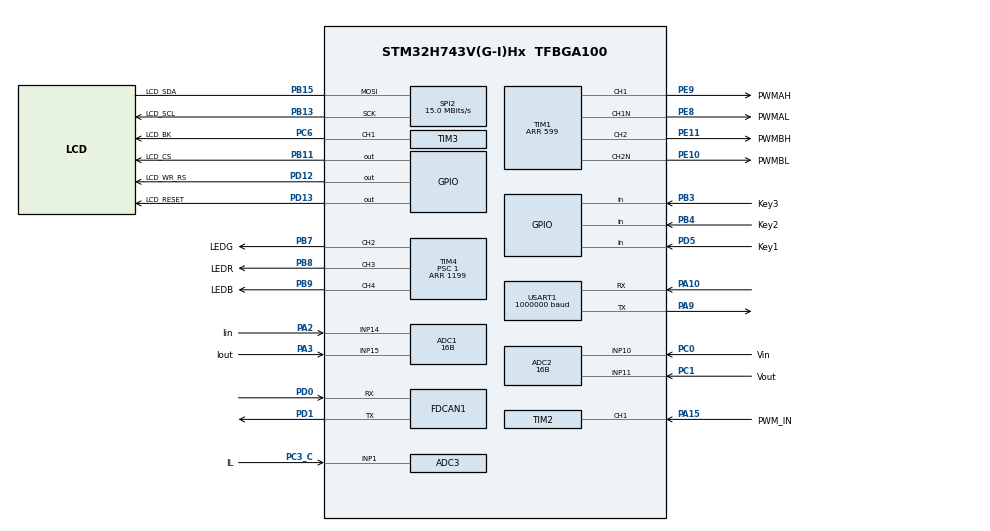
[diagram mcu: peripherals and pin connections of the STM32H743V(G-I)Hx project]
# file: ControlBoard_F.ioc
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ADC1.Channel-1\#ChannelRegularConversion=ADC_CHANNEL_14
ADC1.Channel-2\#ChannelRegularConversion=ADC_CHANNEL_15
ADC1.ClockPrescaler=ADC_CLOCK_SYNC_PCLK_DIV4
ADC1.ClockPrescalerADC3=ADC_CLOCK_SYNC_PCLK_DIV4
ADC1.ConversionDataManagement=ADC_CONVERSIONDATA_DMA_CIRCULAR
ADC1.EOCSelection=ADC_EOC_SEQ_CONV
ADC1.ExternalTrigConv=ADC_EXTERNALTRIG_T1_TRGO
ADC1.NbrOfConversion=2
ADC1.NbrOfConversionFlag=1
ADC1.OffsetNumber-1\#ChannelRegularConversion=ADC_OFFSET_NONE
ADC1.OffsetNumber-2\#ChannelRegularConversion=ADC_OFFSET_NONE
ADC1.OffsetSignedSaturation-1\#ChannelRegularConversion=DISABLE
ADC1.OffsetSignedSaturation-2\#ChannelRegularConversion=DISABLE
ADC1.Overrun=ADC_OVR_DATA_OVERWRITTEN
ADC1.Rank-1\#ChannelRegularConversion=1
ADC1.Rank-2\#ChannelRegularConversion=2
ADC1.Resolution=ADC_RESOLUTION_16B
ADC1.SamplingTime-1\#ChannelRegularConversion=ADC_SAMPLETIME_387CYCLES_5
ADC1.SamplingTime-2\#ChannelRegularConversion=ADC_SAMPLETIME_387CYCLES_5
ADC1.master=1
ADC2.Channel-1\#ChannelRegularConversion=ADC_CHANNEL_10
ADC2.Channel-2\#ChannelRegularConversion=ADC_CHANNEL_11
ADC2.ClockPrescaler=ADC_CLOCK_SYNC_PCLK_DIV4
ADC2.ClockPrescalerADC3=ADC_CLOCK_SYNC_PCLK_DIV4
ADC2.ConversionDataManagement=ADC_CONVERSIONDATA_DMA_CIRCULAR
ADC2.EOCSelection=ADC_EOC_SEQ_CONV
ADC2.ExternalTrigConv=ADC_EXTERNALTRIG_T1_TRGO
ADC2.NbrOfConversion=2
ADC2.NbrOfConversionFlag=1
ADC2.OffsetNumber-1\#ChannelRegularConversion=ADC_OFFSET_NONE
ADC2.OffsetNumber-2\#ChannelRegularConversion=ADC_OFFSET_NONE
ADC2.OffsetSignedSaturation-1\#ChannelRegularConversion=DISABLE
ADC2.OffsetSignedSaturation-2\#ChannelRegularConversion=DISABLE
ADC2.Overrun=ADC_OVR_DATA_OVERWRITTEN
ADC2.Rank-1\#ChannelRegularConversion=1
ADC2.Rank-2\#ChannelRegularConversion=2
ADC2.Resolution=ADC_RESOLUTION_16B
ADC2.SamplingTime-1\#ChannelRegularConversion=ADC_SAMPLETIME_387CYCLES_5
ADC2.SamplingTime-2\#ChannelRegularConversion=ADC_SAMPLETIME_387CYCLES_5
ADC3.Channel-1\#ChannelRegularConversion=ADC_CHANNEL_1
ADC3.ClockPrescaler=ADC_CLOCK_SYNC_PCLK_DIV4
ADC3.ClockPrescalerADC3=ADC_CLOCK_SYNC_PCLK_DIV4
ADC3.ConversionDataManagement=ADC_CONVERSIONDATA_DMA_CIRCULAR
ADC3.EOCSelection=ADC_EOC_SEQ_CONV
ADC3.ExternalTrigConv=ADC_EXTERNALTRIG_T1_TRGO
ADC3.NbrOfConversion=1
ADC3.NbrOfConversionFlag=1
ADC3.OffsetNumber-1\#ChannelRegularConversion=ADC_OFFSET_NONE
ADC3.OffsetSignedSaturation-1\#ChannelRegularConversion=DISABLE
ADC3.Overrun=ADC_OVR_DATA_OVERWRITTEN
ADC3.Rank-1\#ChannelRegularConversion=1
ADC3.Resolution=ADC_RESOLUTION_16B
ADC3.SamplingTime-1\#ChannelRegularConversion=ADC_SAMPLETIME_387CYCLES_5
CORTEX_M7.default_mode_Activation=1
Dma.ADC1.0.Direction=DMA_PERIPH_TO_MEMORY
Dma.ADC1.0.EventEnable=DISABLE
Dma.ADC1.0.FIFOMode=DMA_FIFOMODE_DISABLE
Dma.ADC1.0.Instance=DMA1_Stream0
Dma.ADC1.0.MemDataAlignment=DMA_MDATAALIGN_HALFWORD
Dma.ADC1.0.MemInc=DMA_MINC_ENABLE
Dma.ADC1.0.Mode=DMA_CIRCULAR
Dma.ADC1.0.PeriphDataAlignment=DMA_PDATAALIGN_HALFWORD
Dma.ADC1.0.PeriphInc=DMA_PINC_DISABLE
Dma.ADC1.0.Polarity=HAL_DMAMUX_REQ_GEN_RISING
Dma.ADC1.0.Priority=DMA_PRIORITY_LOW
Dma.ADC1.0.RequestNumber=1
Dma.ADC1.0.SignalID=NONE
Dma.ADC1.0.SyncEnable=DISABLE
Dma.ADC1.0.SyncPolarity=HAL_DMAMUX_SYNC_NO_EVENT
Dma.ADC1.0.SyncRequestNumber=1
Dma.ADC1.0.SyncSignalID=NONE
Dma.ADC2.1.Direction=DMA_PERIPH_TO_MEMORY
Dma.ADC2.1.EventEnable=DISABLE
Dma.ADC2.1.FIFOMode=DMA_FIFOMODE_DISABLE
Dma.ADC2.1.Instance=DMA2_Stream0
Dma.ADC2.1.MemDataAlignment=DMA_MDATAALIGN_HALFWORD
Dma.ADC2.1.MemInc=DMA_MINC_ENABLE
Dma.ADC2.1.Mode=DMA_CIRCULAR
Dma.ADC2.1.PeriphDataAlignment=DMA_PDATAALIGN_HALFWORD
Dma.ADC2.1.PeriphInc=DMA_PINC_DISABLE
Dma.ADC2.1.Polarity=HAL_DMAMUX_REQ_GEN_RISING
Dma.ADC2.1.Priority=DMA_PRIORITY_LOW
Dma.ADC2.1.RequestNumber=1
Dma.ADC2.1.SignalID=NONE
Dma.ADC2.1.SyncEnable=DISABLE
Dma.ADC2.1.SyncPolarity=HAL_DMAMUX_SYNC_NO_EVENT
Dma.ADC2.1.SyncRequestNumber=1
Dma.ADC2.1.SyncSignalID=NONE
Dma.ADC3.2.Direction=DMA_PERIPH_TO_MEMORY
Dma.ADC3.2.EventEnable=DISABLE
Dma.ADC3.2.FIFOMode=DMA_FIFOMODE_DISABLE
Dma.ADC3.2.Instance=DMA1_Stream3
Dma.ADC3.2.MemDataAlignment=DMA_MDATAALIGN_HALFWORD
Dma.ADC3.2.MemInc=DMA_MINC_ENABLE
Dma.ADC3.2.Mode=DMA_CIRCULAR
Dma.ADC3.2.PeriphDataAlignment=DMA_PDATAALIGN_HALFWORD
Dma.ADC3.2.PeriphInc=DMA_PINC_DISABLE
Dma.ADC3.2.Polarity=HAL_DMAMUX_REQ_GEN_RISING
Dma.ADC3.2.Priority=DMA_PRIORITY_LOW
Dma.ADC3.2.RequestNumber=1
Dma.ADC3.2.SignalID=NONE
Dma.ADC3.2.SyncEnable=DISABLE
Dma.ADC3.2.SyncPolarity=HAL_DMAMUX_SYNC_NO_EVENT
Dma.ADC3.2.SyncRequestNumber=1
Dma.ADC3.2.SyncSignalID=NONE
Dma.Request0=ADC1
Dma.Request1=ADC2
Dma.Request2=ADC3
FDCAN1.CalculateBaudRateNominal=999999
FDCAN1.CalculateTimeBitNominal=1000
FDCAN1.CalculateTimeQuantumNominal=41.66666666666667
FDCAN1.DataPrescaler=5
FDCAN1.DataTimeSeg1=17
FDCAN1.DataTimeSeg2=6
FDCAN1.FrameFormat=FDCAN_FRAME_CLASSIC
FDCAN1.NominalPrescaler=5
FDCAN1.NominalTimeSeg1=17
FDCAN1.NominalTimeSeg2=6
FDCAN1.RxFifo0ElmtSize=FDCAN_DATA_BYTES_16
FDCAN1.RxFifo0ElmtsNbr=10
FDCAN1.StdFiltersNbr=1
FDCAN1.TxElmtSize=FDCAN_DATA_BYTES_16
FDCAN1.TxFifoQueueElmtsNbr=10
Mcu.Family=STM32H7
Mcu.Name=STM32H743V(G-I)Hx
Mcu.Package=TFBGA100
NVIC.ADC3_IRQn=true\:0\:0\:false\:false\:true\:true\:true\:true
NVIC.ADC_IRQn=true\:0\:0\:false\:false\:true\:true\:true\:true
NVIC.DMA1_Stream0_IRQn=true\:0\:0\:false\:false\:true\:false\:true\:true
NVIC.DMA1_Stream3_IRQn=true\:0\:0\:false\:false\:true\:false\:true\:true
NVIC.DMA2_Stream0_IRQn=true\:0\:0\:false\:false\:true\:false\:true\:true
NVIC.FDCAN1_IT0_IRQn=true\:0\:0\:false\:false\:true\:true\:true\:true
NVIC.PriorityGroup=NVIC_PRIORITYGROUP_4
NVIC.TIM2_IRQn=true\:0\:0\:false\:false\:true\:true\:true\:true
NVIC.TIM7_IRQn=true\:0\:0\:true\:false\:true\:true\:true\:true
PA10.Mode=Asynchronous
PA10.Signal=USART1_RX
PA13\ (JTMS/SWDIO).Mode=Serial_Wire
PA13\ (JTMS/SWDIO).Signal=DEBUG_JTMS-SWDIO
PA14\ (JTCK/SWCLK).Mode=Serial_Wire
PA14\ (JTCK/SWCLK).Signal=DEBUG_JTCK-SWCLK
PA15\ (JTDI).GPIO_Label=PWM_IN
PA15\ (JTDI).Signal=S_TIM2_CH1_ETR
PA2.GPIO_Label=Iin
PA2.Signal=ADCx_INP14
PA3.GPIO_Label=Iout
PA3.Signal=ADCx_INP15
PA9.Mode=Asynchronous
PA9.Signal=USART1_TX
PB11.GPIO_Label=LCD_CS
PB11.Signal=GPIO_Output
PB13.GPIO_Label=LCD_SCL
PB13.Mode=Simplex_Bidirectional_Master
PB13.Signal=SPI2_SCK
PB15.GPIO_Label=LCD_SDA
PB15.Mode=Simplex_Bidirectional_Master
PB15.Signal=SPI2_MOSI
PB3\ (JTDO/TRACESWO).GPIO_Label=Key3
PB3\ (JTDO/TRACESWO).Signal=GPIO_Input
PB4\ (NJTRST).GPIO_Label=Key2
PB4\ (NJTRST).Signal=GPIO_Input
PB7.GPIO_Label=LEDG
PB7.Signal=S_TIM4_CH2
PB8.GPIO_Label=LEDR
PB8.Signal=S_TIM4_CH3
PB9.GPIO_Label=LEDB
PB9.Signal=S_TIM4_CH4
PC0.GPIO_Label=Vin
PC0.Signal=ADCx_INP10
PC1.GPIO_Label=Vout
PC1.Signal=ADCx_INP11
PC3_C.GPIO_Label=IL
PC3_C.Mode=IN1-Single-Ended
PC3_C.Signal=ADC3_INP1
PC6.GPIO_Label=LCD_BK
PC6.Signal=S_TIM3_CH1
PD0.Mode=FDCAN_Activate
PD0.Signal=FDCAN1_RX
PD1.Mode=FDCAN_Activate
PD1.Signal=FDCAN1_TX
PD12.GPIO_Label=LCD_WR_RS
PD12.Signal=GPIO_Output
PD13.GPIO_Label=LCD_RESET
PD13.Signal=GPIO_Output
PD5.GPIO_Label=Key1
PD5.Signal=GPIO_Input
PE10.GPIO_Label=PWMBL
PE10.GPIO_Speed=GPIO_SPEED_FREQ_VERY_HIGH
PE10.Mode=PWM Generation2 CH2 CH2N
PE10.Signal=TIM1_CH2N
PE11.GPIO_Label=PWMBH
PE11.GPIO_Speed=GPIO_SPEED_FREQ_VERY_HIGH
PE11.Signal=S_TIM1_CH2
PE8.GPIO_Label=PWMAL
PE8.GPIO_Speed=GPIO_SPEED_FREQ_VERY_HIGH
PE8.Mode=PWM Generation1 CH1 CH1N
PE8.Signal=TIM1_CH1N
PE9.GPIO_Label=PWMAH
PE9.GPIO_Speed=GPIO_SPEED_FREQ_VERY_HIGH
PE9.Signal=S_TIM1_CH1
PH0-OSC_IN\ (PH0).Mode=HSE-External-Clock-Source
PH0-OSC_IN\ (PH0).Signal=RCC_OSC_IN
ProjectManager.HeapSize=0x200
ProjectManager.StackSize=0x400
ProjectManager.TargetToolchain=STM32CubeIDE
RCC.ADCFreq_Value=100000000
RCC.APB1Freq_Value=120000000
RCC.APB2Freq_Value=120000000
RCC.APB3Freq_Value=120000000
RCC.APB4Freq_Value=120000000
RCC.CortexFreq_Value=480000000
RCC.D1PPRE=RCC_APB3_DIV2
RCC.D2PPRE1=RCC_APB1_DIV2
RCC.D2PPRE2=RCC_APB2_DIV2
RCC.D3PPRE=RCC_APB4_DIV2
RCC.DIVM1=5
RCC.DIVM2=20
RCC.DIVN1=192
RCC.DIVN2=160
RCC.DIVQ1=8
RCC.HCLKFreq_Value=240000000
RCC.HPRE=RCC_HCLK_DIV2
RCC.PLL2FRACN=0
RCC.PLL3FRACN=0
RCC.PLLFRACN=0
RCC.PLLSourceVirtual=RCC_PLLSOURCE_HSE
RCC.SYSCLKFreq_VALUE=480000000
RCC.SYSCLKSource=RCC_SYSCLKSOURCE_PLLCLK
RCC.Tim1Mul=2
RCC.USBFreq_Value=120000000
SH.ADCx_INP10.0=ADC1_INP10
SH.ADCx_INP10.1=ADC2_INP10,IN10-Single-Ended
SH.ADCx_INP11.0=ADC1_INP11
SH.ADCx_INP11.1=ADC2_INP11,IN11-Single-Ended
SH.ADCx_INP14.0=ADC2_INP14
SH.ADCx_INP14.1=ADC1_INP14,IN14-Single-Ended
SH.ADCx_INP15.0=ADC2_INP15
SH.ADCx_INP15.1=ADC1_INP15,IN15-Single-Ended
SH.S_TIM1_CH1.0=TIM1_CH1,PWM Generation1 CH1 CH1N
SH.S_TIM1_CH2.0=TIM1_CH2,PWM Generation2 CH2 CH2N
SH.S_TIM2_CH1_ETR.0=TIM2_CH1,Input_Capture1_from_TI1
SH.S_TIM3_CH1.0=TIM3_CH1,PWM Generation1 CH1
SH.S_TIM4_CH2.0=TIM4_CH2,PWM Generation2 CH2
SH.S_TIM4_CH3.0=TIM4_CH3,PWM Generation3 CH3
SH.S_TIM4_CH4.0=TIM4_CH4,PWM Generation4 CH4
SPI2.BaudRatePrescaler=SPI_BAUDRATEPRESCALER_8
SPI2.CalculateBaudRate=15.0 MBits/s
SPI2.DataSize=SPI_DATASIZE_8BIT
SPI2.Direction=SPI_DIRECTION_1LINE
SPI2.Mode=SPI_MODE_MASTER
SPI2.VirtualType=VM_MASTER
TIM1.AutoReloadPreload=TIM_AUTORELOAD_PRELOAD_DISABLE
TIM1.AutomaticOutput=TIM_AUTOMATICOUTPUT_ENABLE
TIM1.Channel-PWM\ Generation1\ CH1\ CH1N=TIM_CHANNEL_1
TIM1.Channel-PWM\ Generation2\ CH2\ CH2N=TIM_CHANNEL_2
TIM1.CounterMode=TIM_COUNTERMODE_CENTERALIGNED1
TIM1.DeadTime=50
TIM1.OCFastMode_PWM-PWM\ Generation1\ CH1\ CH1N=TIM_OCFAST_ENABLE
TIM1.OCFastMode_PWM-PWM\ Generation2\ CH2\ CH2N=TIM_OCFAST_ENABLE
TIM1.OCMode_PWM-PWM\ Generation1\ CH1\ CH1N=TIM_OCMODE_PWM2
TIM1.OCMode_PWM-PWM\ Generation2\ CH2\ CH2N=TIM_OCMODE_PWM2
TIM1.OffStateIDLEMode=TIM_OSSI_ENABLE
TIM1.OffStateRunMode=TIM_OSSR_ENABLE
TIM1.Period=599
TIM1.RepetitionCounter=3
TIM1.TIM_MasterOutputTrigger=TIM_TRGO_UPDATE
TIM1.TIM_MasterOutputTrigger2=TIM_TRGO2_RESET
TIM2.AutoReloadPreload=TIM_AUTORELOAD_PRELOAD_ENABLE
TIM2.Channel-Input_Capture1_from_TI1=TIM_CHANNEL_1
TIM2.ICPolarity_CH1=TIM_INPUTCHANNELPOLARITY_BOTHEDGE
TIM2.Period=999
TIM2.Prescaler=119
TIM3.AutoReloadPreload=TIM_AUTORELOAD_PRELOAD_ENABLE
TIM3.Channel-PWM\ Generation1\ CH1=TIM_CHANNEL_1
TIM3.Period=1199
TIM3.Prescaler=1
TIM4.AutoReloadPreload=TIM_AUTORELOAD_PRELOAD_ENABLE
TIM4.Channel-PWM\ Generation2\ CH2=TIM_CHANNEL_2
TIM4.Channel-PWM\ Generation3\ CH3=TIM_CHANNEL_3
TIM4.Channel-PWM\ Generation4\ CH4=TIM_CHANNEL_4
TIM4.OCPolarity_2=TIM_OCPOLARITY_LOW
TIM4.OCPolarity_3=TIM_OCPOLARITY_LOW
TIM4.OCPolarity_4=TIM_OCPOLARITY_LOW
TIM4.Period=1199
TIM4.Prescaler=1
TIM7.AutoReloadPreload=TIM_AUTORELOAD_PRELOAD_ENABLE
TIM7.Period=11999
TIM7.Prescaler=199
USART1.BaudRate=1000000
USART1.VirtualMode-Asynchronous=VM_ASYNC
VP_TIM1_VS_ClockSourceINT.Mode=Internal
VP_TIM2_VS_ClockSourceINT.Mode=Internal
VP_TIM3_VS_ClockSourceINT.Mode=Internal
VP_TIM4_VS_ClockSourceINT.Mode=Internal
VP_TIM7_VS_ClockSourceINT.Mode=Enable_Timer
board=custom

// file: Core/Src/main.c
/* USER CODE BEGIN Header */
/**
 ******************************************************************************
 * @file           : main.c
 * @brief          : Main program body
 ******************************************************************************
 * @attention
 *
 * Copyright (c) 2024 STMicroelectronics.
 * All rights reserved.
 *
 * This software is licensed under terms that can be found in the LICENSE file
 * in the root directory of this software component.
 * If no LICENSE file comes with this software, it is provided AS-IS.
 *
 ******************************************************************************
 */
/* USER CODE END Header */
#include "main.h"
#include "adc.h"
#include "dma.h"
#include "fdcan.h"
#include "spi.h"
#include "tim.h"
#include "usart.h"
#include "gpio.h"

/* USER CODE BEGIN Includes */
#include <usermain.hpp>
/* USER CODE END Includes */

void SystemClock_Config(void);
static void MPU_Config(void);

int main(void)
{

  /* MPU Configuration--------------------------------------------------------*/
  MPU_Config();

  /* MCU Configuration--------------------------------------------------------*/

  /* Reset of all peripherals, Initializes the Flash interface and the Systick. */
  HAL_Init();

  /* Configure the system clock */
  SystemClock_Config();

  /* Initialize all configured peripherals */
  MX_GPIO_Init();
  MX_DMA_Init();
  MX_FDCAN1_Init();
  MX_TIM1_Init();
  MX_ADC2_Init();
  MX_ADC3_Init();
  MX_ADC1_Init();
  MX_USART1_UART_Init();
  MX_SPI2_Init();
  MX_TIM3_Init();
  MX_TIM4_Init();
  MX_TIM7_Init();
  MX_TIM2_Init();
  /* USER CODE BEGIN 2 */
    Usermain();
  /* USER CODE END 2 */

  /* Infinite loop */
    while (1) {

    }
}

void SystemClock_Config(void)
{
  RCC_OscInitTypeDef RCC_OscInitStruct = {0};
  RCC_ClkInitTypeDef RCC_ClkInitStruct = {0};

  /** Supply configuration update enable
  */
  HAL_PWREx_ConfigSupply(PWR_LDO_SUPPLY);

  /** Configure the main internal regulator output voltage
  */
  __HAL_PWR_VOLTAGESCALING_CONFIG(PWR_REGULATOR_VOLTAGE_SCALE1);

  while(!__HAL_PWR_GET_FLAG(PWR_FLAG_VOSRDY)) {}

  __HAL_RCC_SYSCFG_CLK_ENABLE();
  __HAL_PWR_VOLTAGESCALING_CONFIG(PWR_REGULATOR_VOLTAGE_SCALE0);

  while(!__HAL_PWR_GET_FLAG(PWR_FLAG_VOSRDY)) {}

  /** Initializes the RCC Oscillators according to the specified parameters
  * in the RCC_OscInitTypeDef structure.
  */
  RCC_OscInitStruct.OscillatorType = RCC_OSCILLATORTYPE_HSE;
  RCC_OscInitStruct.HSEState = RCC_HSE_BYPASS;
  RCC_OscInitStruct.PLL.PLLState = RCC_PLL_ON;
  RCC_OscInitStruct.PLL.PLLSource = RCC_PLLSOURCE_HSE;
  RCC_OscInitStruct.PLL.PLLM = 5;
  RCC_OscInitStruct.PLL.PLLN = 192;
  RCC_OscInitStruct.PLL.PLLP = 2;
  RCC_OscInitStruct.PLL.PLLQ = 8;
  RCC_OscInitStruct.PLL.PLLR = 2;
  RCC_OscInitStruct.PLL.PLLRGE = RCC_PLL1VCIRANGE_2;
  RCC_OscInitStruct.PLL.PLLVCOSEL = RCC_PLL1VCOWIDE;
  RCC_OscInitStruct.PLL.PLLFRACN = 0;
  if (HAL_RCC_OscConfig(&RCC_OscInitStruct) != HAL_OK)
  {
    Error_Handler();
  }

  /** Initializes the CPU, AHB and APB buses clocks
  */
  RCC_ClkInitStruct.ClockType = RCC_CLOCKTYPE_HCLK|RCC_CLOCKTYPE_SYSCLK
                              |RCC_CLOCKTYPE_PCLK1|RCC_CLOCKTYPE_PCLK2
                              |RCC_CLOCKTYPE_D3PCLK1|RCC_CLOCKTYPE_D1PCLK1;
  RCC_ClkInitStruct.SYSCLKSource = RCC_SYSCLKSOURCE_PLLCLK;
  RCC_ClkInitStruct.SYSCLKDivider = RCC_SYSCLK_DIV1;
  RCC_ClkInitStruct.AHBCLKDivider = RCC_HCLK_DIV2;
  RCC_ClkInitStruct.APB3CLKDivider = RCC_APB3_DIV2;
  RCC_ClkInitStruct.APB1CLKDivider = RCC_APB1_DIV2;
  RCC_ClkInitStruct.APB2CLKDivider = RCC_APB2_DIV2;
  RCC_ClkInitStruct.APB4CLKDivider = RCC_APB4_DIV2;

  if (HAL_RCC_ClockConfig(&RCC_ClkInitStruct, FLASH_LATENCY_4) != HAL_OK)
  {
    Error_Handler();
  }
}

 /* MPU Configuration */

void MPU_Config(void)
{
  MPU_Region_InitTypeDef MPU_InitStruct = {0};

  /* Disables the MPU */
  HAL_MPU_Disable();

  /** Initializes and configures the Region and the memory to be protected
  */
  MPU_InitStruct.Enable = MPU_REGION_ENABLE;
  MPU_InitStruct.Number = MPU_REGION_NUMBER0;
  MPU_InitStruct.BaseAddress = 0x0;
  MPU_InitStruct.Size = MPU_REGION_SIZE_4GB;
  MPU_InitStruct.SubRegionDisable = 0x87;
  MPU_InitStruct.TypeExtField = MPU_TEX_LEVEL0;
  MPU_InitStruct.AccessPermission = MPU_REGION_NO_ACCESS;
  MPU_InitStruct.DisableExec = MPU_INSTRUCTION_ACCESS_DISABLE;
  MPU_InitStruct.IsShareable = MPU_ACCESS_SHAREABLE;
  MPU_InitStruct.IsCacheable = MPU_ACCESS_NOT_CACHEABLE;
  MPU_InitStruct.IsBufferable = MPU_ACCESS_NOT_BUFFERABLE;

  HAL_MPU_ConfigRegion(&MPU_InitStruct);
  /* Enables the MPU */
  HAL_MPU_Enable(MPU_PRIVILEGED_DEFAULT);

}

void Error_Handler(void)
{
    __disable_irq();
    while (1) {
    }
}
